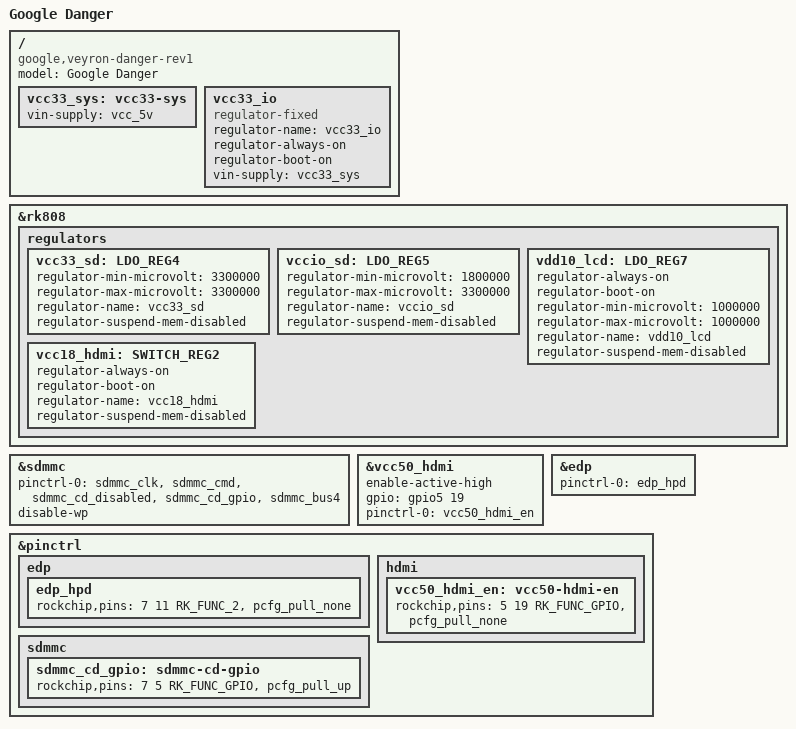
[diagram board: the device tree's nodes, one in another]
/*
 * Google Veyron Danger Rev 1 board device tree source
 *
 * Copyright 2015 Google, Inc
 *
 * This program is free software; you can redistribute it and/or modify
 * it under the terms of the GNU General Public License version 2 as
 * published by the Free Software Foundation.
 */

/dts-v1/;
#include "rk3288-veyron.dtsi"
#include "rk3288-veyron-lpddr.dtsi"
#include "rk3288-veyron-analog-audio.dtsi"
#include "rk3288-veyron-edp.dtsi"
#include "rk3288-veyron-ethernet.dtsi"
#include "rk3288-veyron-sdmmc.dtsi"

/ {
	model = "Google Danger";
	compatible = "google,veyron-danger-rev1", "google,veyron-danger",
	             "google,veyron", "rockchip,rk3288";

	vcc33_sys: vcc33-sys {
		vin-supply = <&vcc_5v>;
	};

	vcc33_io: vcc33_io {
		compatible = "regulator-fixed";
		regulator-name = "vcc33_io";
		regulator-always-on;
		regulator-boot-on;
		vin-supply = <&vcc33_sys>;
		/* This is gated by vcc_18 too */
	};
};

&rk808 {
	/delete-property/ vcc6-supply;

	regulators {
		/* vcc33_io is sourced directly from vcc33_sys */
		/delete-node/ LDO_REG1;

		/* these regulators are swapped in rev1 */
		/delete-node/ LDO_REG4;
		/delete-node/ LDO_REG5;
		vcc33_sd: LDO_REG4 {
			regulator-min-microvolt = <3300000>;
			regulator-max-microvolt = <3300000>;
			regulator-name = "vcc33_sd";
			regulator-suspend-mem-disabled;
		};

		vccio_sd: LDO_REG5 {
			regulator-min-microvolt = <1800000>;
			regulator-max-microvolt = <3300000>;
			regulator-name = "vccio_sd";
			regulator-suspend-mem-disabled;
		};

		/* This is not a pwren anymore, but the real power supply */
		vdd10_lcd: LDO_REG7 {
			regulator-always-on;
			regulator-boot-on;
			regulator-min-microvolt = <1000000>;
			regulator-max-microvolt = <1000000>;
			regulator-name = "vdd10_lcd";
			regulator-suspend-mem-disabled;
		};

		vcc18_hdmi: SWITCH_REG2 {
			regulator-always-on;
			regulator-boot-on;
			regulator-name = "vcc18_hdmi";
			regulator-suspend-mem-disabled;
		};
	};
};

&sdmmc {
	pinctrl-names = "default";
	pinctrl-0 = <&sdmmc_clk &sdmmc_cmd &sdmmc_cd_disabled &sdmmc_cd_gpio
			&sdmmc_bus4>;
	disable-wp;
};

&vcc50_hdmi {
	enable-active-high;
	gpio = <&gpio5 19 GPIO_ACTIVE_HIGH>;
	pinctrl-names = "default";
	pinctrl-0 = <&vcc50_hdmi_en>;
};

&edp {
	pinctrl-names = "default";
	pinctrl-0 = <&edp_hpd>;
};

&pinctrl {
	edp {
		edp_hpd: edp_hpd {
			rockchip,pins = <7 11 RK_FUNC_2 &pcfg_pull_none>;
		};
	};

	hdmi {
		vcc50_hdmi_en: vcc50-hdmi-en {
			rockchip,pins = <5 19 RK_FUNC_GPIO &pcfg_pull_none>;
		};
	};

	sdmmc {
		/* There's an external pullup which goes to the wrong place,
		 * use the internal pullup instead which will win (~50k
		 * internal wins over 100k external). */
		sdmmc_cd_gpio: sdmmc-cd-gpio {
			rockchip,pins = <7 5 RK_FUNC_GPIO &pcfg_pull_up>;
		};
	};
};
